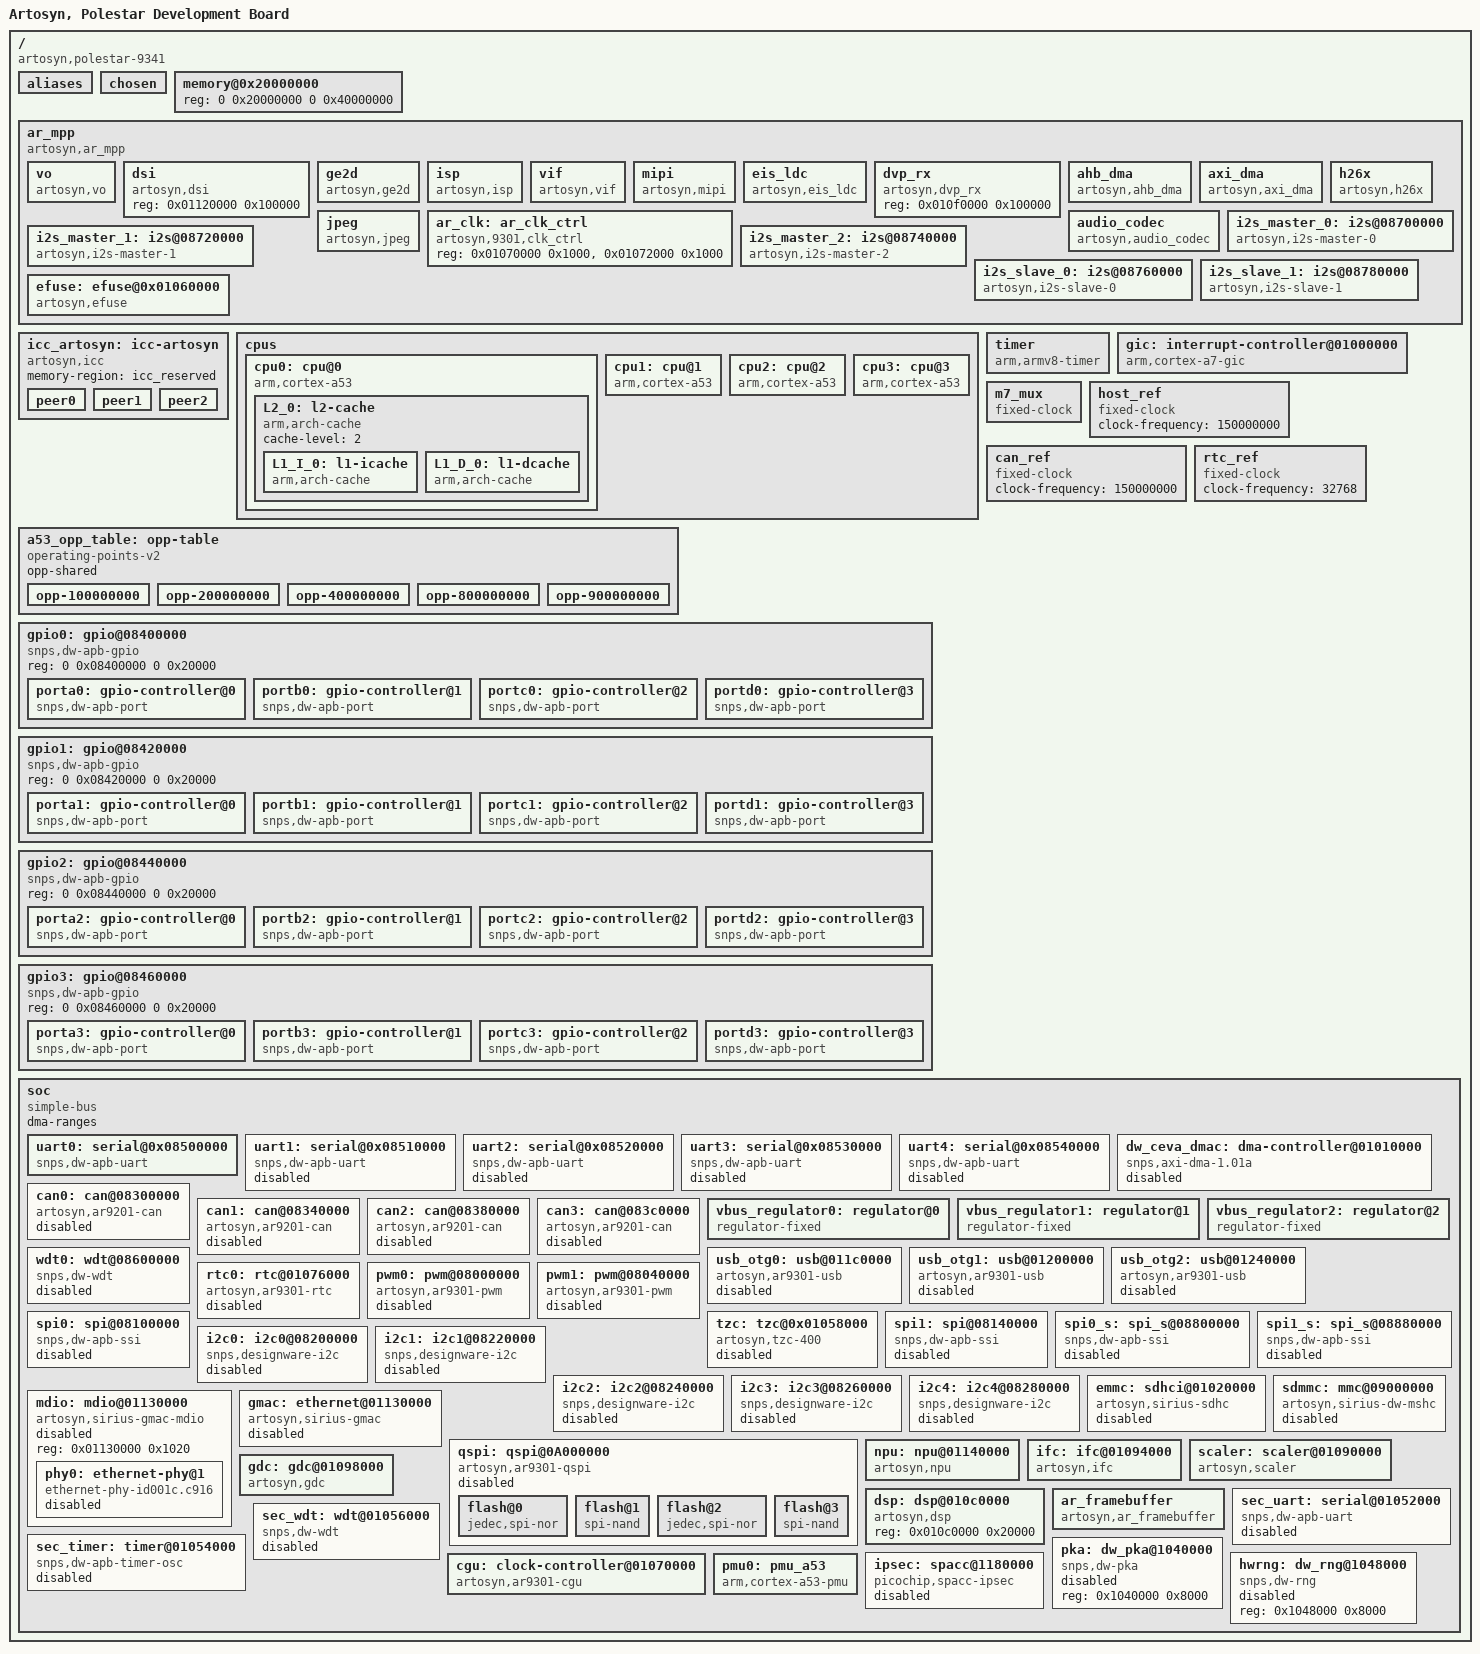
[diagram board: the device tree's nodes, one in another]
/*
 * Copyright 2015 Artosyn Co., Ltd.
 *
 * This file is dual-licensed: you can use it either under the terms
 * of the GPL or the X11 license, at your option. Note that this dual
 * licensing only applies to this file, and not this project as a
 * whole.
 *
 *  a) This file is free software; you can redistribute it and/or
 *     modify it under the terms of the GNU General Public License as
 *     published by the Free Software Foundation; either version 2 of the
 *     License, or (at your option) any later version.
 *
 *     This file is distributed in the hope that it will be useful,
 *     but WITHOUT ANY WARRANTY; without even the implied warranty of
 *     MERCHANTABILITY or FITNESS FOR A PARTICULAR PURPOSE.  See the
 *     GNU General Public License for more details.
 *
 * Or, alternatively,
 *
 *  b) Permission is hereby granted, free of charge, to any person
 *     obtaining a copy of this software and associated documentation
 *     files (the "Software"), to deal in the Software without
 *     restriction, including without limitation the rights to use,
 *     copy, modify, merge, publish, distribute, sublicense, and/or
 *     sell copies of the Software, and to permit persons to whom the
 *     Software is furnished to do so, subject to the following
 *     conditions:
 *
 *     The above copyright notice and this permission notice shall be
 *     included in all copies or substantial portions of the Software.
 *
 *     THE SOFTWARE IS PROVIDED "AS IS", WITHOUT WARRANTY OF ANY KIND,
 *     EXPRESS OR IMPLIED, INCLUDING BUT NOT LIMITED TO THE WARRANTIES
 *     OF MERCHANTABILITY, FITNESS FOR A PARTICULAR PURPOSE AND
 *     NONINFRINGEMENT. IN NO EVENT SHALL THE AUTHORS OR COPYRIGHT
 *     HOLDERS BE LIABLE FOR ANY CLAIM, DAMAGES OR OTHER LIABILITY,
 *     WHETHER IN AN ACTION OF CONTRACT, TORT OR OTHERWISE, ARISING
 *     OTHER DEALINGS IN THE SOFTWARE.
 */
#include <dt-bindings/gpio/gpio.h>
#include <dt-bindings/interrupt-controller/arm-gic.h>
#include <dt-bindings/ar93xx_common.h>
#include <dt-bindings/clock/ar_clk.h>
/ {
	model = "Artosyn, Polestar Development Board";
	compatible = "artosyn,polestar-9341";

	#address-cells = <2>;
	#size-cells = <2>;

	interrupt-parent = <&gic>;

	aliases {
		uart0 = &uart0;
		i2c0 = &i2c0;
		i2c1 = &i2c1;
		i2c2 = &i2c2;
		i2c3 = &i2c3;
		i2c4 = &i2c4;
	};

	chosen {
		bootargs = "console=ttyS0,115200n8 earlycon=uart,mmio32,0x08500000 user_debug=31 loglevel=8 coredump_filter=0x21";
		stdout-path = &uart0;
	};

	memory@0x20000000 {
		device_type = "memory";
		reg = <0 0x20000000 0 0x40000000>;
	};

	ar_mpp {
		#address-cells = <1>;
		#size-cells = <1>;
		ranges;
		dma-ranges;

		compatible = "artosyn,ar_mpp";

		interrupts = <GIC_SPI 157 IRQ_TYPE_LEVEL_HIGH>,  // scalyer
			     <GIC_SPI 125 IRQ_TYPE_LEVEL_HIGH>; 
		interrupt-parent = <&gic>;

		vo {
			compatible = "artosyn,vo";
			interrupts =    <GIC_SPI  116 IRQ_TYPE_LEVEL_HIGH>;  //vo 
			reg = <0x010a0000 0x100000>;
		};

		dsi {
			compatible = "artosyn,dsi";
			reg = <0x01120000 0x100000>;
		};

		ge2d {
			compatible = "artosyn,ge2d";
			interrupts =    <GIC_SPI  129 IRQ_TYPE_LEVEL_HIGH>,  //ge2d 1 
			                <GIC_SPI  134 IRQ_TYPE_LEVEL_HIGH>;  //ge2d 2 
			reg = <0x010af000 0x001000>;
		};

		isp {
			compatible = "artosyn,isp";
			interrupts =    <GIC_SPI  117 IRQ_TYPE_LEVEL_HIGH>;  //isp 
			reg = <0x02400000 0x100000>;
		};

		vif {
			compatible = "artosyn,vif";
			interrupts =    <GIC_SPI  106 IRQ_TYPE_LEVEL_HIGH>;  //vif 
			reg = <0x01100000 0x100000>;
		};

		mipi {
			compatible = "artosyn,mipi";
			interrupts =    <GIC_SPI  102 IRQ_TYPE_LEVEL_HIGH>,  //mipi0 
					        <GIC_SPI  103 IRQ_TYPE_LEVEL_HIGH>,  //mipi1 
						    <GIC_SPI  104 IRQ_TYPE_LEVEL_HIGH>,  //mipi2
			                <GIC_SPI  105 IRQ_TYPE_LEVEL_HIGH>;  //mipi3 
			reg = <0x01110000 0x100000>;
		};

		eis_ldc {
			compatible = "artosyn,eis_ldc";
			interrupts =    <GIC_SPI  126 IRQ_TYPE_LEVEL_HIGH>;  //eis_ldc  
			reg = <0x01090000 0x100000>;
		};

		dvp_rx {
			compatible = "artosyn,dvp_rx";
			reg = <0x010f0000 0x100000>;
		};

		ahb_dma {
			compatible = "artosyn,ahb_dma";
			interrupts =    <GIC_SPI  86 IRQ_TYPE_LEVEL_HIGH>,  // ahb dma ch0
					<GIC_SPI  87 IRQ_TYPE_LEVEL_HIGH>,  // ahb dma ch1
					<GIC_SPI  88 IRQ_TYPE_LEVEL_HIGH>,  // ahb dma ch2
					<GIC_SPI  89 IRQ_TYPE_LEVEL_HIGH>,  // ahb dma ch3
					<GIC_SPI  90 IRQ_TYPE_LEVEL_HIGH>,  // ahb dma ch4
					<GIC_SPI  91 IRQ_TYPE_LEVEL_HIGH>,  // ahb dma ch5
					<GIC_SPI  92 IRQ_TYPE_LEVEL_HIGH>,  // ahb dma ch6
					<GIC_SPI  93 IRQ_TYPE_LEVEL_HIGH>;  // ahb dma ch7
			reg = <0x0b000000 0x1000000>,
				<0x08b00030 4>;
		};

		axi_dma {
			compatible = "artosyn,axi_dma";
			interrupts = 	<GIC_SPI  107 IRQ_TYPE_LEVEL_HIGH>, // axi dma ch0
					<GIC_SPI  108 IRQ_TYPE_LEVEL_HIGH>, // axi dma ch1
					<GIC_SPI  109 IRQ_TYPE_LEVEL_HIGH>, // axi dma ch2
					<GIC_SPI  110 IRQ_TYPE_LEVEL_HIGH>; // axi dma ch3
			reg = <0x01010000 0x10000>;
		};

		h26x {
			compatible = "artosyn,h26x";
			interrupts = <GIC_SPI 114 IRQ_TYPE_LEVEL_HIGH>;  // h26x
			reg = <0x010d0000 0x10000>;
			conf_file_path = "/usrdata/local/factory/codec_factory_cfg.cjson";
			// vpu_timeout_us = <500>;
		};

		jpeg {
			compatible = "artosyn,jpeg";
			interrupts = <GIC_SPI 115 IRQ_TYPE_LEVEL_HIGH>;  // jpeg
			reg = <0x010b0000 0x10000>;
		};

		ar_clk: ar_clk_ctrl {
			compatible = "artosyn,9301,clk_ctrl";
			reg = 	<0x01070000 0x1000>, //cgu regitster
				<0x01072000 0x1000>; //abb regitster
		};

		audio_codec {
			compatible = "artosyn,audio_codec";
			interrupts =  <GIC_SPI  99 IRQ_TYPE_LEVEL_HIGH>;  // audio
			reg = <0x08900000 0x100000>;
			aio-dev-idx = <0>;
		};

		i2s_master_0: i2s@08700000 {
			compatible = "artosyn,i2s-master-0";
			interrupts = <GIC_SPI 82 IRQ_TYPE_LEVEL_HIGH>;
			reg = <0x08700000 0x20000>,
				<0x08b0000c 0x4>,
				<0x08b0000c 0x4>;
			aio-dev-idx = <1>;
		};

		i2s_master_1: i2s@08720000 {
			compatible = "artosyn,i2s-master-1";
			interrupts = <GIC_SPI 83 IRQ_TYPE_LEVEL_HIGH>;
			reg = <0x08720000 0x20000>,
				<0x08b0000c 0x4>,
				<0x08b0000c 0x4>;
			aio-dev-idx = <2>;
		};

		i2s_master_2: i2s@08740000 {
			compatible = "artosyn,i2s-master-2";
			interrupts = <GIC_SPI 84 IRQ_TYPE_LEVEL_HIGH>;
			reg = <0x08740000 0x20000>,
				<0x08b0000c 0x4>,
				<0x08b0000c 0x4>;
			aio-dev-idx = <3>;
		};

		i2s_slave_0: i2s@08760000 {
			compatible = "artosyn,i2s-slave-0";
			reg = <0x08760000 0x20000>,
				<0x08b0000c 0x4>,
				<0x08b0000c 0x4>;
			aio-dev-idx = <4>;
		};

		i2s_slave_1: i2s@08780000 {
			compatible = "artosyn,i2s-slave-1";
			reg = <0x08780000 0x20000>,
				<0x08b0000c 0x4>,
				<0x08b0000c 0x4>;
			aio-dev-idx = <5>;
		};

		efuse: efuse@0x01060000 {
			compatible = "artosyn,efuse";
			reg = <0x01060000 0x1000>;
			size = <0x200>;
		};
	};

	icc_artosyn:icc-artosyn {
		compatible = "artosyn,icc";
		memory-region = <&icc_reserved>;

		peer0 {
			type = "cortex-a";
			trigger-irq = <5>;
			cpu-id = <0>;
		};

		peer1 {
			type = "cortex-a";
			trigger-irq = <5>;
			cpu-id = <3>;
		};

		peer2 {
			type = "ceva";
			cpu-id = <0>;
			trigger-address = <0x010c4008>;
			clr-irq-address = <0x010c4020>;
			interrupts = <GIC_SPI 118 IRQ_TYPE_LEVEL_HIGH>;
		};

	};

	cpus:cpus {
		#address-cells = <2>;
		#size-cells = <0>;

		cpu0: cpu@0 {
			compatible = "arm,cortex-a53", "arm,armv8";
			device_type = "cpu";
			enable-method = "ar-spin-table";
			clocks = <&cgu INDEX_CLK(AR_CLK_PLL_ARM)>;
			//clock-frequency = <1000000000>;
			reg = <0x00 0x00>;
			//cci-control-port = <&cci_control>;
			next-level-cache = <&L2_0>;
			operating-points-v2 = <&a53_opp_table>;
			L2_0: l2-cache {
				compatible = "arm,arch-cache";
				cache-level = <2>;
				L1_I_0: l1-icache {
					compatible = "arm,arch-cache";
				};
				L1_D_0: l1-dcache {
					compatible = "arm,arch-cache";
				};
			};
		};

		cpu1: cpu@1 {
			compatible = "arm,cortex-a53", "arm,armv8";
			device_type = "cpu";
			enable-method = "ar-spin-table";
			cpu-release-addr = <0x0 0x017c0000>;
			clocks = <&cgu INDEX_CLK(AR_CLK_PLL_ARM)>;
			//clock-frequency = <1000000000>;
			reg = <0x00 0x01>;
			//cci-control-port = <&cci_control>;
			next-level-cache = <&L2_0>;
			operating-points-v2 = <&a53_opp_table>;
		};

		cpu2: cpu@2 {
			compatible = "arm,cortex-a53", "arm,armv8";
			device_type = "cpu";
			enable-method = "ar-spin-table";
			cpu-release-addr = <0x0 0x017c0008>;
			clocks = <&cgu INDEX_CLK(AR_CLK_PLL_ARM)>;
			//clock-frequency = <1000000000>;
			reg = <0x00 0x02>;
			//cci-control-port = <&cci_control>;
			next-level-cache = <&L2_0>;
			operating-points-v2 = <&a53_opp_table>;
		};

		cpu3: cpu@3 {
			compatible = "arm,cortex-a53", "arm,armv8";
			device_type = "cpu";
			enable-method = "ar-spin-table";
			cpu-release-addr = <0x0 0x017c0010>;
			clocks = <&cgu INDEX_CLK(AR_CLK_PLL_ARM)>;
			//clock-frequency = <1000000000>;
			reg = <0x00 0x03>;
			//cci-control-port = <&cci_control>;
			next-level-cache = <&L2_0>;
			operating-points-v2 = <&a53_opp_table>;
		};
	};

	a53_opp_table: opp-table {
		compatible = "operating-points-v2";
		opp-shared;

		opp-100000000 {
			opp-hz = /bits/ 64 <100000000>;
			opp-microvolt = <900000>;
			clock-latency-ns = <150000>;
			opp-suspend;
		};

		opp-200000000 {
			opp-hz = /bits/ 64 <200000000>;
			opp-microvolt = <900000>;
			clock-latency-ns = <150000>;
		};

		opp-400000000 {
			opp-hz = /bits/ 64 <400000000>;
			opp-microvolt = <900000>;
			clock-latency-ns = <150000>;
		};

		opp-800000000 {
			opp-hz = /bits/ 64 <800000000>;
			opp-microvolt = <900000>;
			clock-latency-ns = <150000>;
		};

		opp-900000000 {
			opp-hz = /bits/ 64 <900000000>;
			opp-microvolt = <900000>;
			clock-latency-ns = <150000>;
		};
	};

	timer: timer {
		compatible = "arm,armv8-timer";
		interrupts = <GIC_PPI 13 IRQ_TYPE_LEVEL_LOW>,
		             <GIC_PPI 14 IRQ_TYPE_LEVEL_LOW>,
		             <GIC_PPI 11 IRQ_TYPE_LEVEL_LOW>,
		             <GIC_PPI 10 IRQ_TYPE_LEVEL_LOW>;

		clock-frequency = <250000000>;

		always-on;
		interrupt-parent = <&gic>;
		arm,cpu-registers-not-fw-configured;
	};

	gic: interrupt-controller@01000000 {
		compatible = "arm,cortex-a7-gic","arm,cortex-a15-gic","arm,gic-400";
		#interrupt-cells = <3>;
		#address-cells = <1>;
		interrupt-controller;

		reg = <0 0x01001000 0 0x1000>,
		      <0 0x01002000 0 0x1000>,
		      <0 0x01004000 0 0x2000>,
		      <0 0x01006000 0 0x2000>;
		/*interrupts = <GIC_PPI 9 (GIC_CPU_MASK_SIMPLE(4) | IRQ_TYPE_LEVEL_HIGH)>;*/
	};

	m7_mux: m7_mux{
		compatible = "fixed-clock";
		#clock-cells = <0>;
		clock-frequency = <150000000>;
		clock-output-names = "i2c_clk","spi_clk","uart_clk";
	};

	host_ref:host_ref{
		compatible = "fixed-clock";
		#clock-cells = <0>;
		clock-frequency = <150000000>;
	};

	can_ref:can_ref{
		compatible = "fixed-clock";
		#clock-cells = <0>;
		clock-frequency = <150000000>;
	};

	rtc_ref:rtc_ref{
		compatible = "fixed-clock";
		#clock-cells = <0>;
		clock-frequency = <32768>;
	};

	gpio0: gpio@08400000 {
		compatible = "snps,dw-apb-gpio";
		reg = <0 0x08400000 0 0x20000>;
		#address-cells = <1>;
		#size-cells = <0>;

		porta0: gpio-controller@0 {
			compatible = "snps,dw-apb-port";
			gpio-controller;
			#gpio-cells = <2>;
			snps,nr-gpios = <8>;
			reg = <0>;
			interrupt-controller;
			#interrupt-cells = <2>;
			interrupts = <GIC_SPI 77 IRQ_TYPE_LEVEL_HIGH>;
		};

		portb0: gpio-controller@1 {
			compatible = "snps,dw-apb-port";
			gpio-controller;
			#gpio-cells = <2>;
			snps,nr-gpios = <8>;
			reg = <1>;
		};

		portc0: gpio-controller@2 {
			compatible = "snps,dw-apb-port";
			gpio-controller;
			#gpio-cells = <2>;
			snps,nr-gpios = <8>;
			reg = <2>;
		};

		portd0: gpio-controller@3 {
			compatible = "snps,dw-apb-port";
			gpio-controller;
			#gpio-cells = <2>;
			snps,nr-gpios = <8>;
			reg = <3>;
		};
	};


	gpio1: gpio@08420000 {
		compatible = "snps,dw-apb-gpio";
		reg = <0 0x08420000 0 0x20000>;
		#address-cells = <1>;
		#size-cells = <0>;

		porta1: gpio-controller@0 {
			compatible = "snps,dw-apb-port";
			gpio-controller;
			#gpio-cells = <2>;
			snps,nr-gpios = <8>;
			reg = <0>;
			interrupt-controller;
			#interrupt-cells = <2>;
			interrupts = <GIC_SPI 78 IRQ_TYPE_LEVEL_HIGH>;
		};

		portb1: gpio-controller@1 {
			compatible = "snps,dw-apb-port";
			gpio-controller;
			#gpio-cells = <2>;
			snps,nr-gpios = <8>;
			reg = <1>;
		};

		portc1: gpio-controller@2 {
			compatible = "snps,dw-apb-port";
			gpio-controller;
			#gpio-cells = <2>;
			snps,nr-gpios = <8>;
			reg = <2>;
		};

		portd1: gpio-controller@3 {
			compatible = "snps,dw-apb-port";
			gpio-controller;
			#gpio-cells = <2>;
			snps,nr-gpios = <8>;
			reg = <3>;
		};
	};

	gpio2: gpio@08440000{
		compatible = "snps,dw-apb-gpio";
		reg = <0 0x08440000 0 0x20000>;
		#address-cells = <1>;
		#size-cells = <0>;

		porta2: gpio-controller@0 {
			compatible = "snps,dw-apb-port";
			gpio-controller;
			#gpio-cells = <2>;
			snps,nr-gpios = <8>;
			reg = <0>;
			interrupt-controller;
			#interrupt-cells = <2>;
			interrupts = <GIC_SPI 79 IRQ_TYPE_LEVEL_HIGH>;
		};

		portb2: gpio-controller@1 {
			compatible = "snps,dw-apb-port";
			gpio-controller;
			#gpio-cells = <2>;
			snps,nr-gpios = <8>;
			reg = <1>;
		};

		portc2: gpio-controller@2 {
			compatible = "snps,dw-apb-port";
			gpio-controller;
			#gpio-cells = <2>;
			snps,nr-gpios = <8>;
			reg = <2>;
		};

		portd2: gpio-controller@3 {
			compatible = "snps,dw-apb-port";
			gpio-controller;
			#gpio-cells = <2>;
			snps,nr-gpios = <8>;
			reg = <3>;
		};
	};

	gpio3: gpio@08460000{
		compatible = "snps,dw-apb-gpio";
		reg = <0 0x08460000 0 0x20000>;
		#address-cells = <1>;
		#size-cells = <0>;

		porta3: gpio-controller@0 {
			compatible = "snps,dw-apb-port";
			gpio-controller;
			#gpio-cells = <2>;
			snps,nr-gpios = <8>;
			reg = <0>;
			interrupt-controller;
			#interrupt-cells = <2>;
			interrupts = <GIC_SPI 80 IRQ_TYPE_LEVEL_HIGH>;
		};

		portb3: gpio-controller@1 {
			compatible = "snps,dw-apb-port";
			gpio-controller;
			#gpio-cells = <2>;
			snps,nr-gpios = <8>;
			reg = <1>;
		};

		portc3: gpio-controller@2 {
			compatible = "snps,dw-apb-port";
			gpio-controller;
			#gpio-cells = <2>;
			snps,nr-gpios = <8>;
			reg = <2>;
		};

		portd3: gpio-controller@3 {
			compatible = "snps,dw-apb-port";
			gpio-controller;
			#gpio-cells = <2>;
			snps,nr-gpios = <8>;
			reg = <3>;
		};
	};

	soc {
		compatible = "simple-bus";
		#address-cells = <1>;
		#size-cells = <1>;
		ranges;
		dma-ranges;

		uart0: serial@0x08500000 {
			compatible = "snps,dw-apb-uart";
			reg = <0x08500000 0x400>;
			interrupts = <GIC_SPI 45 IRQ_TYPE_LEVEL_HIGH>;
			reg-shift = <2>;
			reg-io-width = <4>;
			clock-frequency = <150000000>;
			status = "okay";
		};

		uart1: serial@0x08510000 {
			compatible = "snps,dw-apb-uart";
			reg = <0x08510000 0x400>;
			interrupts = <GIC_SPI 46 IRQ_TYPE_LEVEL_HIGH>;
			reg-shift = <2>;
			reg-io-width = <4>;
			clock-frequency = <150000000>;
			status = "disabled";
		};

		uart2: serial@0x08520000 {
			compatible = "snps,dw-apb-uart";
			reg = <0x08520000 0x400>;
			interrupts = <GIC_SPI 47 IRQ_TYPE_LEVEL_HIGH>;
			reg-shift = <2>;
			reg-io-width = <4>;
			clock-frequency = <150000000>;
			status = "disabled";
		};

		uart3: serial@0x08530000 {
			compatible = "snps,dw-apb-uart";
			reg = <0x08530000 0x400>;
			interrupts = <GIC_SPI 48 IRQ_TYPE_LEVEL_HIGH>;
			reg-shift = <2>;
			reg-io-width = <4>;
			clock-frequency = <150000000>;
			status = "disabled";
		};

		uart4: serial@0x08540000 {
			compatible = "snps,dw-apb-uart";
			reg = <0x08540000 0x400>;
			interrupts = <GIC_SPI 49 IRQ_TYPE_LEVEL_HIGH>;
			reg-shift = <2>;
			reg-io-width = <4>;
			clock-frequency = <150000000>;
			status = "disabled";
		};

		dw_ceva_dmac:dma-controller@01010000 {
			compatible = "snps,axi-dma-1.01a";
			reg = <0x01010000 0x1000>;
			interrupts = <GIC_SPI 107 IRQ_TYPE_LEVEL_HIGH>,
				     <GIC_SPI 108 IRQ_TYPE_LEVEL_HIGH>,
				     <GIC_SPI 109 IRQ_TYPE_LEVEL_HIGH>,
				     <GIC_SPI 110 IRQ_TYPE_LEVEL_HIGH>;
			clocks = <&m7_mux>, <&m7_mux>;
			clock-names = "core-clk", "cfgr-clk";

			//#dma-cells = <1>;
			dma-channels = <4>;
			snps,dma-masters = <1>;
			snps,data-width = <4>;
			snps,block-size = <0x3ffff 0x3ffff 0x3ffff 0x3ffff>;
			snps,priority = <0 1 2 3>;
			snps,axi-max-burst-len = <16>;
			status = "disabled";
		};

		can0: can@08300000 {
			compatible = "artosyn,ar9201-can";
			reg =  <0x08300000 0x40000>;
			interrupts = <GIC_SPI 72 IRQ_TYPE_LEVEL_HIGH>;
			clock-names     = "host_clk", "can_clk";
			clocks          = <&host_ref>, <&can_ref>;
			status = "disabled";
		};

		can1: can@08340000 {
			compatible = "artosyn,ar9201-can";
			reg =  <0x08340000 0x40000>;
			interrupts = <GIC_SPI 73 IRQ_TYPE_LEVEL_HIGH>;
			clock-names     = "host_clk", "can_clk";
			clocks          = <&host_ref>, <&can_ref>;
			status = "disabled";
		};

		can2: can@08380000 {
			compatible = "artosyn,ar9201-can";
			reg =  <0x08380000 0x40000>;
			interrupts = <GIC_SPI 74 IRQ_TYPE_LEVEL_HIGH>;
			clock-names     = "host_clk", "can_clk";
			clocks          = <&host_ref>, <&can_ref>;
			status = "disabled";
		};

		can3: can@083c0000 {
			compatible = "artosyn,ar9201-can";
			reg =  <0x083c0000 0x40000>;
			interrupts = <GIC_SPI 75 IRQ_TYPE_LEVEL_HIGH>;
			clock-names     = "host_clk", "can_clk";
			clocks          = <&host_ref>, <&can_ref>;
			status = "disabled";
		};

		vbus_regulator0: regulator@0 {
			compatible = "regulator-fixed";
			regulator-name = "usb_otg0_vbus";
			regulator-min-microvolt = <5000000>;
			regulator-max-microvolt = <5000000>;
			gpio = <&portb1 5 GPIO_ACTIVE_HIGH>;
			enable-active-high;
		};

		vbus_regulator1: regulator@1 {
			compatible = "regulator-fixed";
			regulator-name = "usb_otg1_vbus";
			regulator-min-microvolt = <5000000>;
			regulator-max-microvolt = <5000000>;
			gpio = <&portb1 6 GPIO_ACTIVE_HIGH>;
			enable-active-high;
		};

		vbus_regulator2: regulator@2 {
			compatible = "regulator-fixed";
			regulator-name = "usb_otg2_vbus";
			regulator-min-microvolt = <5000000>;
			regulator-max-microvolt = <5000000>;
			gpio = <&portb1 7 GPIO_ACTIVE_HIGH>;
			enable-active-high;
		};

		usb_otg0: usb@011c0000 {
			compatible = "artosyn,ar9301-usb";
			reg = <0x011c0000 0x40000>;
			interrupts = <GIC_SPI 122 IRQ_TYPE_LEVEL_HIGH>;
			//clocks = <&cru HCLK_OTG0>;
			//clock-names = "otg";
			dr_mode = "peripheral";
			//dr_mode = "host";
			g-np-tx-fifo-size = <32>;
			g-rx-fifo-size = <768>;
			g-tx-fifo-size = <768 512 512 32 16 16 16 16 16 16>;
			g-use-dma;
			//phys = <&usbphy0>;
			//phy-names = "usb2-phy";
			vbus-supply = <&vbus_regulator0>;
			status = "disabled";
		};

		usb_otg1: usb@01200000 {
			compatible = "artosyn,ar9301-usb";
			reg = <0x01200000 0x40000>;
			interrupts = <GIC_SPI 123 IRQ_TYPE_LEVEL_HIGH>;
			//clocks = <&cru HCLK_OTG0>;
			//clock-names = "otg";
			dr_mode = "host";
			//dr_mode = "peripheral";
			g-np-tx-fifo-size = <32>;
			g-rx-fifo-size = <768>;
			g-tx-fifo-size = <768 512 512 32 16 16 16 16 16 16>;
			g-use-dma;
			//phys = <&usbphy0>;
			//phy-names = "usb2-phy";
			vbus-supply = <&vbus_regulator1>;
			status = "disabled";
		};

		usb_otg2: usb@01240000 {
			compatible = "artosyn,ar9301-usb";
			reg = <0x01240000 0x40000>;
			interrupts = <GIC_SPI 124 IRQ_TYPE_LEVEL_HIGH>;
			//clocks = <&cru HCLK_OTG0>;
			//clock-names = "otg";
			//dr_mode = "peripheral";
			dr_mode = "host";
			g-np-tx-fifo-size = <32>;
			g-rx-fifo-size = <768>;
			g-tx-fifo-size = <768 512 512 32 16 16 16 16 16 16>;
			g-use-dma;
			//phys = <&usbphy0>;
			//phy-names = "usb2-phy";
			vbus-supply = <&vbus_regulator2>;
			status = "disabled";
		};

		wdt0: wdt@08600000 {
			compatible = "snps,dw-wdt";
			reg = <0x08600000 0x100000>;
			interrupts = <GIC_SPI 76 IRQ_TYPE_LEVEL_HIGH>;
			clock-names     = "host_clk";
			clocks          = <&host_ref>;
			status = "disabled";
		};

		rtc0: rtc@01076000 {
			compatible = "artosyn,ar9301-rtc";
			reg = <0x01076000 0x1000>;
			interrupts = <GIC_SPI 136 IRQ_TYPE_LEVEL_HIGH>;
			clock-names     = "rtc_clk";
			clocks          = <&rtc_ref>;
			status = "disabled";
		};

		pwm0: pwm@08000000 {
			compatible = "artosyn,ar9301-pwm";
			reg = <0x08000000 0x1000>;
			clock-names     = "host_clk";
			clocks          = <&host_ref>;
			#pwm-cells	= <2>;
			status = "disabled";
		};

		pwm1: pwm@08040000 {
			compatible = "artosyn,ar9301-pwm";
			reg = <0x08040000 0x1000>;
			clock-names     = "host_clk";
			clocks          = <&host_ref>;
			#pwm-cells	= <2>;
			status = "disabled";
		};

		tzc: tzc@0x01058000 {
			compatible = "artosyn,tzc-400";
			//    tzc-0: 0x64539000    tzc-0: 0x64538000
			reg = <0x01059000 0x1000>, <0x01058000 0x1000>;
			interrupts = <GIC_SPI 32 IRQ_TYPE_LEVEL_HIGH>;
			tzc-region-idx = <1>;
			status = "disabled";
		};

		spi0: spi@08100000 {
			compatible = "snps,dw-apb-ssi";
			reg = <0x08100000 0x40000>;
			reg-io-width = <4>;
			num-cs = <4>;
			component = <0>;
			is_slave = <0>;
			enable_dma = <0>;
			eeprom_mode = <1>;
			interrupts = <GIC_SPI 66 IRQ_TYPE_LEVEL_HIGH>;
			clocks = <&host_ref>;
			clock-names = "spi_clk";
			status = "disabled";
		};

		spi1: spi@08140000 {
			compatible = "snps,dw-apb-ssi";
			reg = <0x08140000 0x40000>;
			reg-io-width = <4>;
			num-cs = <4>;
			//rx-sample-delay-ns = <3>;
			component = <0>;
			is_slave = <0>;
			enable_dma = <0>;
			eeprom_mode = <1>;
			interrupts = <GIC_SPI 67 IRQ_TYPE_LEVEL_HIGH>;
			clocks = <&host_ref>;
			clock-names = "spi_clk";
			status = "disabled";
		};

		spi0_s: spi_s@08800000 {
			compatible = "snps,dw-apb-ssi";
			reg = <0x08800000 0x40000>;
			reg-io-width = <4>;
			num-cs = <4>;
			component = <0>;
			is_slave = <1>;
			enable_dma = <0>;
			eeprom_mode = <1>;
			interrupts = <GIC_SPI 94 IRQ_TYPE_LEVEL_HIGH>;
			clocks = <&host_ref>;
			clock-names = "spi_clk";
			status = "disabled";
		};

		spi1_s: spi_s@08880000 {
			compatible = "snps,dw-apb-ssi";
			reg = <0x08880000 0x40000>;
			reg-io-width = <4>;
			num-cs = <4>;
			//rx-sample-delay-ns = <3>;
			component = <0>;
			is_slave = <1>;
			enable_dma = <0>;
			eeprom_mode = <1>;
			interrupts = <GIC_SPI 95 IRQ_TYPE_LEVEL_HIGH>;
			clocks = <&host_ref>;
			clock-names = "spi_clk";
			status = "disabled";
		};

		i2c0: i2c0@08200000 {
			compatible = "snps,designware-i2c";
			#address-cells = <1>;
			#size-cells = <0>;
			reg = <0x08200000 0x20000>;
			interrupts = <GIC_SPI 68 IRQ_TYPE_LEVEL_HIGH>;
			clock-frequency = <400000>;
			i2c-sda-hold-time-ns = <300>;
			i2c-sda-falling-time-ns = <300>;
			i2c-scl-falling-time-ns = <300>;
			clocks = <&m7_mux>;
			clock-names = "i2c_clk";
			status = "disabled";
		};

		i2c1: i2c1@08220000 {
			compatible = "snps,designware-i2c";
			#address-cells = <1>;
			#size-cells = <0>;
			reg = <0x08220000 0x20000>;
			interrupts = <GIC_SPI 69 IRQ_TYPE_LEVEL_HIGH>;
			clock-frequency = <400000>;
			i2c-sda-hold-time-ns = <300>;
			i2c-sda-falling-time-ns = <300>;
			i2c-scl-falling-time-ns = <300>;
			clocks = <&m7_mux>;
			clock-names = "i2c_clk";
			status = "disabled";
		};

		i2c2: i2c2@08240000 {
			compatible = "snps,designware-i2c";
			#address-cells = <1>;
			#size-cells = <0>;
			reg = <0x08240000 0x20000>;
			interrupts = <GIC_SPI 70 IRQ_TYPE_LEVEL_HIGH>;
			clock-frequency = <400000>;
			i2c-sda-hold-time-ns = <300>;
			i2c-sda-falling-time-ns = <300>;
			i2c-scl-falling-time-ns = <300>;
			clocks = <&m7_mux>;
			clock-names = "i2c_clk";
			status = "disabled";
		};

		i2c3: i2c3@08260000 {
			compatible = "snps,designware-i2c";
			#address-cells = <1>;
			#size-cells = <0>;
			reg = <0x08260000 0x20000>;
			interrupts = <GIC_SPI 71 IRQ_TYPE_LEVEL_HIGH>;
			clock-frequency = <400000>;
			i2c-sda-hold-time-ns = <300>;
			i2c-sda-falling-time-ns = <300>;
			i2c-scl-falling-time-ns = <300>;
			clocks = <&m7_mux>;
			clock-names = "i2c_clk";
			status = "disabled";
		};

		i2c4: i2c4@08280000 {
			compatible = "snps,designware-i2c";
			#address-cells = <1>;
			#size-cells = <0>;
			reg = <0x08280000 0x20000>;
			interrupts = <GIC_SPI 81 IRQ_TYPE_LEVEL_HIGH>;
			clock-frequency = <400000>;
			i2c-sda-hold-time-ns = <300>;
			i2c-sda-falling-time-ns = <300>;
			i2c-scl-falling-time-ns = <300>;
			clocks = <&m7_mux>;
			clock-names = "i2c_clk";
			status = "disabled";
		};

		emmc: sdhci@01020000 {
			compatible = "artosyn,sirius-sdhc";
			reg = <0x01020000 0x2000>;
			interrupts = <GIC_SPI 101 IRQ_TYPE_LEVEL_HIGH>;
			max-frequency = <200000000>;
			card-detect-delay = <200>;
			num-slots = <1>;
			bus-width = <8>;
			full-pwr-cycle;
			cap-mmc-highspeed;
			cap-mmc-hw-reset;
			disable-wp;
			non-removable;
			no-sdio;
			no-sd;

			voltage-ranges = <3300 3300>;
			no-1-8-v;
			status = "disabled";
		};

		sdmmc:  mmc@09000000 {
			compatible = "artosyn,sirius-dw-mshc";
			reg = <0x09000000 0x1000>;
			interrupts = <GIC_SPI 85 IRQ_TYPE_LEVEL_HIGH>;
			clock-frequency = <100000000>;
			clock-freq-min-max = <400000 100000000>;
			card-detect-delay = <200>;
			num-slots = <1>;
			bus-width = <4>;
			full-pwr-cycle;
			cap-sd-highspeed;
			cap-mmc-hw-reset;
			disable-wp;
			sd-uhs-sdr12;
			sd-uhs-sdr25;
			sd-uhs-sdr50;
			sd-uhs-sdr104;
			no-mmc;
			no-sdio;
			status = "disabled";
		};

		mdio: mdio@01130000 {
			reg = <0x01130000 0x1020>;
			compatible = "artosyn,sirius-gmac-mdio";
			#address-cells = <1>;
			#size-cells = <0>;
			status = "disabled";

			phy0: ethernet-phy@1 {
				compatible = "ethernet-phy-id001c.c916","ethernet-phy-ieee802.3-c22";
				reg = <1>;
				interrupts = <GIC_SPI 168 IRQ_TYPE_LEVEL_HIGH>;
				max-speed = <100>;
				status = "disabled";
			};
		};

		gmac: ethernet@01130000 {
			compatible = "artosyn,sirius-gmac";
			reg = <0x01130000 0x1020>;
			interrupts = <GIC_SPI 100 IRQ_TYPE_LEVEL_HIGH>;
			mac-address = [00 00 01 02 03 04]; /*This should not be here if uboot has set mac already*/
			phy-mode = "rgmii";
			phy-handle = <&phy0>;
			tzc-handle = <&tzc>;
			tx-fifo-depth = <3>;
			tx-fifo-depth-1000 = <2>;
			tx-bd-num = <64>; /*total 128 bds, rx-bd-num = 128 - tx-bd-num*/
			tx-enhance;
			rx-enhance;
			status = "disabled";
		};

		qspi: qspi@0A000000 {
			#address-cells = <1>;
			#size-cells = <0>;
			compatible = "artosyn,ar9301-qspi";
			reg = <0x0A000000 0x1000>,
				<0x01070020 0x40>,
				<0x0B000000 0x1000>,
				<0x08B00030 0x40>;
			reg-names = "qspi_base", "cgu_base", "dma_base", "hs_sel_base";
			interrupts = <GIC_SPI 98 IRQ_TYPE_LEVEL_HIGH>;
			clock-frequency = <150000000>;
			dma-channel = <0>;
			timing-cfg = <0>;
			status = "disabled";

			flash@0 {
				compatible = "jedec,spi-nor";
				reg = <SPI_NOR_CS0>;
				spi-max-frequency = <150000000>;
			};
			flash@1 {
				compatible = "spi-nand";
				reg = <SPI_NAND_CS0>;
				spi-max-frequency = <150000000>;
			};
			flash@2 {
				compatible = "jedec,spi-nor";
				reg = <SPI_NOR_CS1>;
				spi-max-frequency = <150000000>;
			};
			flash@3 {
				compatible = "spi-nand";
				reg = <SPI_NAND_CS1>;
				spi-max-frequency = <150000000>;
			};
		};

		npu:npu@01140000 {
			compatible = "artosyn,npu";
			reg = <0x01140000 0x20000>;
			control = <0x01070000>;
			dma_control = <0xc>; /*chan 0 no sec, non cachable*/
			npu_sec_control = <1>; /*chan 0 no sec, 1 sec*/
			interrupts = <GIC_SPI 128 IRQ_TYPE_LEVEL_HIGH>;
			cb_to_arm = <1>;
		};

		ifc:ifc@01094000 {
			compatible = "artosyn,ifc";
			reg = <0x01094000 0x1000>;
			control = <0x01070000>;
			interrupts = <GIC_SPI 127 IRQ_TYPE_LEVEL_HIGH>;
		};

		scaler:scaler@01090000 {
			compatible = "artosyn,scaler";
			reg = <0x01090000 0x1000>;
			control = <0x01070000>;
			interrupts = <GIC_SPI 125 IRQ_TYPE_LEVEL_HIGH>;
		};

		gdc:gdc@01098000 {
			compatible = "artosyn,gdc";
			reg = <0x01098000 0x1000>;
			control = <0x01070000>;
			interrupts = <GIC_SPI 126 IRQ_TYPE_LEVEL_HIGH>;
		};

		dsp:dsp@010c0000 {
			compatible = "artosyn,dsp";
			reg = <0x010c0000 0x20000>;
		};

		ar_framebuffer: ar_framebuffer {
			compatible = "artosyn,ar_framebuffer";
		};

		sec_uart:serial@01052000 {
			compatible = "snps,dw-apb-uart";
			reg = <0x01052000 0x2000>;
			interrupts = <GIC_SPI 37 IRQ_TYPE_LEVEL_HIGH>;
			reg-shift = <2>;
			reg-io-width = <4>;
			clock-frequency = <150000000>;
			status = "disabled";
		};

		sec_timer:timer@01054000 {
			compatible = "snps,dw-apb-timer-osc", "snps,dw-apb-timer";
			reg = <0x01054000 0x2000>;
			interrupts = <GIC_SPI 38 IRQ_TYPE_LEVEL_HIGH>;
			clock-frequency = <150000000>;
			status = "disabled";
		};

		sec_wdt:wdt@01056000 {
			compatible = "snps,dw-wdt";
			reg = <0x01056000 0x2000>;
			interrupts = <GIC_SPI 39 IRQ_TYPE_LEVEL_HIGH>;
			clock-names     = "host_clk";
			clocks          = <&host_ref>;
			status = "disabled";
		};

		ipsec:spacc@1180000 {
			compatible = "picochip,spacc-ipsec";
			reg = <0x1180000 0x10000>;
			interrupts = <GIC_SPI 35 IRQ_TYPE_LEVEL_HIGH>;
			clock-names     = "host_clk";
			clocks          = <&host_ref>;
			status = "disabled";
		};

		pka:dw_pka@1040000 {
			compatible = "snps,dw-pka";
			reg = <0x1040000 0x8000>;
			status = "disabled";
		};

		hwrng:dw_rng@1048000 {
			compatible = "snps,dw-rng";
			reg = <0x1048000 0x8000>;
			status = "disabled";
		};

		cgu: clock-controller@01070000 {
			compatible = "artosyn,ar9301-cgu";
			reg = 	<0x01070000 0x1000>,
				<0x01074020 0x1000>,
				<0x010c0000 0x1000>,
				<0x010e0000 0x1000>;
			#clock-cells = <1>;
			status = "okay";
		};

		pmu0:pmu_a53 {
			compatible = "arm,cortex-a53-pmu";
			interrupts = 	<GIC_SPI 9  IRQ_TYPE_LEVEL_HIGH>,
					<GIC_SPI 10 IRQ_TYPE_LEVEL_HIGH>,
					<GIC_SPI 11 IRQ_TYPE_LEVEL_HIGH>,
					<GIC_SPI 12 IRQ_TYPE_LEVEL_HIGH>;
			interrupt-affinity = 	<&cpu0>,
						<&cpu1>,
						<&cpu2>,
						<&cpu3>;
		};
	};
};
